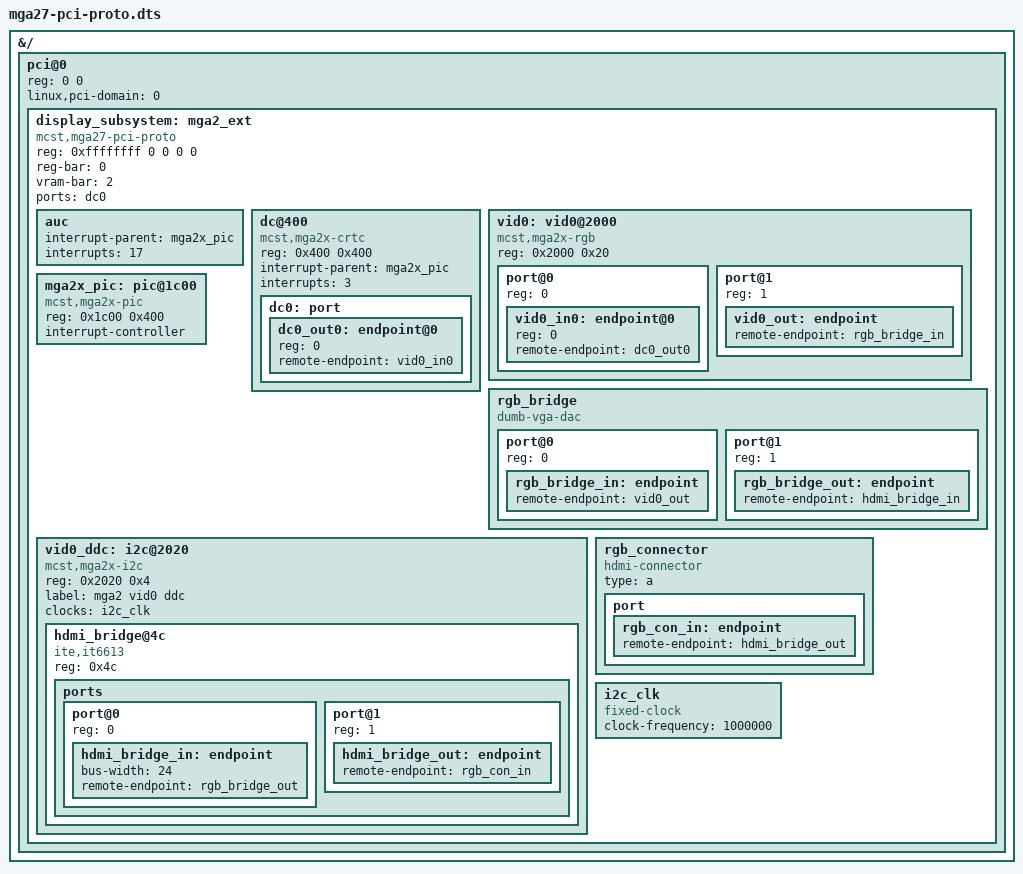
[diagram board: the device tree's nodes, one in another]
/*
 * SPDX-License-Identifier: GPL-2.0
 * Copyright (c) 2023 MCST
 */

/dts-v1/;
/plugin/;

&{/} {
	#address-cells = <1>;
	#size-cells = <1>;
	pci@0 {
		reg = <0 0>;
		linux,pci-domain = <0>;
		/* 1:1 translation, max size (48-bit) of e2k address space */
		ranges = <0 0 0 0 0x10000 0>;
		#address-cells = <3>;
		#size-cells = <2>;
		/* reg: DDDDDDDD bbbbbbbb dddddfff 00000000 */
		display_subsystem: mga2_ext {
			reg = <0xffffffff 0 0 0 0>;
			compatible = "mcst,mga27-pci-proto";
		};
	};
};

#define VID0_STS "okay"

&display_subsystem {
	reg-bar = <0>;
	vram-bar = <2>;
	ports = <&dc0>;

	#address-cells = <1>;
	#size-cells = <1>;
	auc {
		interrupt-parent = <&mga2x_pic>;
		interrupts = <17>;
	};

	dc@400 {
		compatible = "mcst,mga2x-crtc";
		reg = <0x400 0x400>;

		interrupt-parent = <&mga2x_pic>;
		interrupts = <3>;

		dc0: port {
			#address-cells = <1>;
			#size-cells = <0>;

			dc0_out0: endpoint@0 {
				reg = <0>;
				remote-endpoint = <&vid0_in0>;
			};
		};
	};
	vid0: vid0@2000 {
		reg = <0x2000 0x20>;
		status = VID0_STS;
	};

	mga2x_pic: pic@1c00 {
		compatible = "mcst,mga2x-pic";
		reg = <0x1c00 0x400>;
		interrupt-controller;
		#interrupt-cells = <1>;
	};

	rgb_bridge: rgb_bridge {
		status = VID0_STS;
	};

	vid0_ddc: i2c@2020 {
		reg = <0x2020 0x4>;
		status = VID0_STS;
	};

	rgb_connector: rgb_connector {
		status = VID0_STS;
	};

	i2c_clk: i2c_clk {
		compatible = "fixed-clock";
		#clock-cells = <0>;
		clock-frequency = <1000000>;
	};

};

&vid0 {
	compatible = "mcst,mga2x-rgb";

	#address-cells = <1>;
	#size-cells = <0>;

	port@0 {
		reg = <0>;
		#address-cells = <1>;
		#size-cells = <0>;
		vid0_in0: endpoint@0 {
			reg = <0>;
			remote-endpoint = <&dc0_out0>;
		};
	};
	port@1 {
		reg = <1>;
		vid0_out: endpoint {
			remote-endpoint = <&rgb_bridge_in>;
		};
	};
};

&vid0_ddc {
	compatible = "mcst,mga2x-i2c";
	label = "mga2 vid0 ddc";
	#address-cells = <1>;
	#size-cells = <0>;
	clocks = <&i2c_clk>;

	hdmi_bridge@4c {
		compatible = "ite,it6613";
		reg = <0x4c>;

		ports {
			#address-cells = <1>;
            #size-cells = <0>;

			port@0 {
				reg = <0>;
				hdmi_bridge_in: endpoint {
					bus-width = <24>;
					remote-endpoint = <&rgb_bridge_out>;
				};
			};

			port@1 {
				reg = <1>;
				hdmi_bridge_out: endpoint {
					remote-endpoint = <&rgb_con_in>;
				};
			};
		};
	};
};

&rgb_bridge {
	compatible = "dumb-vga-dac";

	#address-cells = <1>;
	#size-cells = <0>;

	port@0 {
		reg = <0>;

		rgb_bridge_in: endpoint {
			remote-endpoint = <&vid0_out>;
		};
	};
	port@1 {
		reg = <1>;

		rgb_bridge_out: endpoint {
			remote-endpoint = <&hdmi_bridge_in>;
		};
	};
};

&rgb_connector {
	compatible = "hdmi-connector";

	type = "a";

	port {
		rgb_con_in: endpoint {
			remote-endpoint = <&hdmi_bridge_out>;
		};
	};
};
